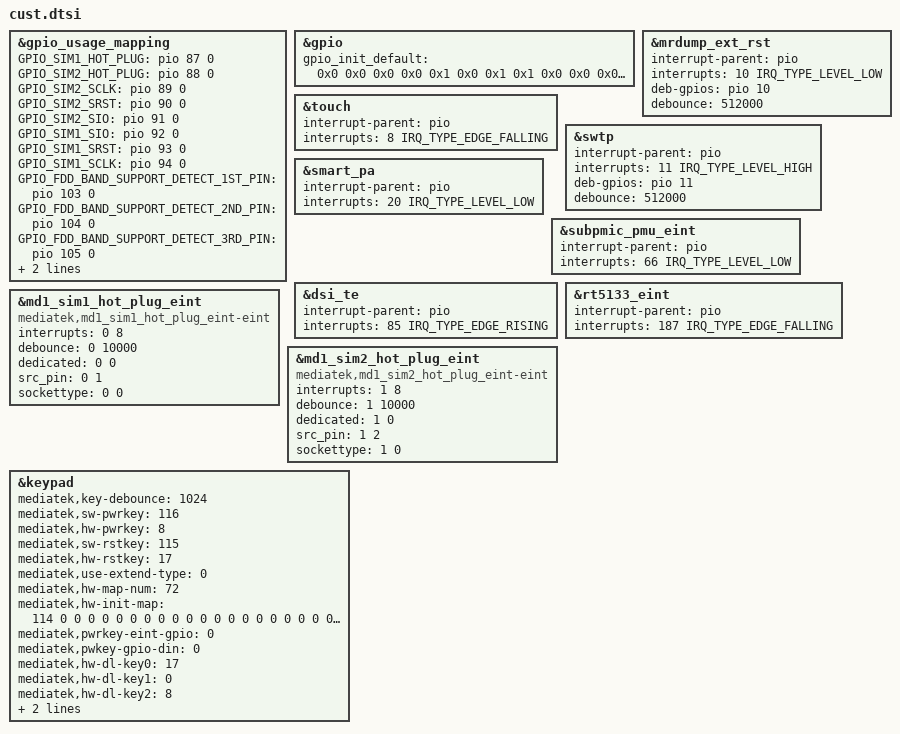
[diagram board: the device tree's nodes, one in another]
/*
 * Manually generated by Mashopy <eliasgheeraert@gmail.com>.
 * 2023-08-16 14:00:00
 * Do Not Modify The File.
*/

/*************************
 * ADC DTSI File
*************************/



/*************************
 * CLK_BUF DTSI File
*************************/



/*************************
 * I2C DTSI File
*************************/



/*************************
 * GPIO DTSI File
*************************/

&gpio_usage_mapping {
	GPIO_SIM1_HOT_PLUG = <&pio 87 0>;
	GPIO_SIM2_HOT_PLUG = <&pio 88 0>;
	GPIO_SIM2_SCLK = <&pio 89 0>;
	GPIO_SIM2_SRST = <&pio 90 0>;
	GPIO_SIM2_SIO = <&pio 91 0>;
	GPIO_SIM1_SIO = <&pio 92 0>;
	GPIO_SIM1_SRST = <&pio 93 0>;
	GPIO_SIM1_SCLK = <&pio 94 0>;
	GPIO_FDD_BAND_SUPPORT_DETECT_1ST_PIN = <&pio 103 0>;
	GPIO_FDD_BAND_SUPPORT_DETECT_2ND_PIN = <&pio 104 0>;
	GPIO_FDD_BAND_SUPPORT_DETECT_3RD_PIN = <&pio 105 0>;
	GPIO_FDD_BAND_SUPPORT_DETECT_4TH_PIN = <&pio 106 0>;
};

&gpio{
	gpio_init_default = <0x0 0x0 0x0 0x0 0x1 0x0 0x1 0x1 0x0 0x0 0x0 0x1 0x0 0x1 0x2 0x0 0x0 0x0 0x1 0x0 0x1 0x3 0x0 0x1 0x0 0x1 0x0 0x1 0x4 0x0 0x0 0x0 0x1 0x0 0x1 0x5 0x0 0x0 0x0 0x1 0x0 0x1 0x6 0x4 0x0 0x0 0x0 0x0 0x1 0x7 0x4 0x0 0x0 0x0 0x0 0x1 0x8 0x0 0x0 0x0 0x0 0x0 0x1 0x9 0x0 0x0 0x0 0x1 0x0 0x1 0xa 0x0 0x0 0x0 0x1 0x1 0x1 0xb 0x0 0x0 0x0 0x1 0x1 0x1 0xc 0x0 0x0 0x0 0x0 0x0 0x1 0xd 0x0 0x0 0x0 0x1 0x0 0x1 0xe 0x0 0x0 0x0 0x1 0x0 0x1 0xf 0x0 0x1 0x0 0x1 0x0 0x1 0x10 0x6 0x0 0x0 0x1 0x0 0x1 0x11 0x6 0x0 0x0 0x1 0x0 0x1 0x12 0x2 0x0 0x0 0x1 0x0 0x1 0x13 0x0 0x0 0x0 0x1 0x0 0x1 0x14 0x0 0x0 0x0 0x1 0x0 0x1 0x15 0x0 0x0 0x0 0x0 0x0 0x1 0x16 0x0 0x0 0x0 0x0 0x0 0x1 0x17 0x0 0x0 0x0 0x1 0x0 0x1 0x18 0x2 0x0 0x0 0x1 0x0 0x1 0x19 0x0 0x0 0x0 0x1 0x0 0x1 0x1a 0x2 0x0 0x0 0x0 0x0 0x1 0x1b 0x2 0x0 0x0 0x0 0x0 0x1 0x1c 0x2 0x0 0x0 0x1 0x0 0x1 0x1d 0x2 0x0 0x0 0x0 0x0 0x1 0x1e 0x0 0x0 0x0 0x0 0x0 0x1 0x1f 0x0 0x0 0x0 0x0 0x0 0x1 0x20 0x0 0x0 0x0 0x1 0x0 0x1 0x21 0x0 0x0 0x0 0x0 0x0 0x1 0x22 0x0 0x1 0x0 0x1 0x0 0x1 0x23 0x0 0x1 0x0 0x1 0x0 0x1 0x24 0x0 0x0 0x0 0x1 0x0 0x1 0x25 0x0 0x0 0x0 0x1 0x0 0x1 0x26 0x1 0x0 0x0 0x0 0x0 0x1 0x27 0x1 0x0 0x0 0x1 0x0 0x1 0x28 0x1 0x0 0x0 0x1 0x1 0x1 0x29 0x1 0x0 0x0 0x1 0x1 0x1 0x2a 0x1 0x0 0x0 0x1 0x1 0x1 0x2b 0x1 0x0 0x0 0x1 0x1 0x1 0x2c 0x1 0x0 0x0 0x0 0x0 0x1 0x2d 0x1 0x0 0x0 0x0 0x0 0x1 0x2e 0x1 0x0 0x0 0x0 0x0 0x1 0x2f 0x1 0x0 0x0 0x0 0x0 0x1 0x30 0x1 0x0 0x0 0x1 0x0 0x1 0x31 0x1 0x0 0x0 0x1 0x1 0x1 0x32 0x1 0x0 0x0 0x1 0x1 0x1 0x33 0x1 0x0 0x0 0x0 0x0 0x1 0x34 0x1 0x0 0x0 0x0 0x0 0x1 0x35 0x1 0x0 0x0 0x0 0x0 0x1 0x36 0x1 0x0 0x0 0x1 0x0 0x1 0x37 0x0 0x0 0x0 0x1 0x0 0x1 0x38 0x0 0x0 0x0 0x1 0x0 0x1 0x39 0x1 0x0 0x0 0x1 0x1 0x1 0x3a 0x1 0x0 0x0 0x1 0x1 0x1 0x3b 0x1 0x0 0x0 0x1 0x1 0x1 0x3c 0x1 0x0 0x0 0x1 0x1 0x1 0x3d 0x1 0x0 0x0 0x0 0x0 0x1 0x3e 0x0 0x1 0x0 0x1 0x0 0x1 0x3f 0x0 0x0 0x0 0x1 0x0 0x1 0x40 0x0 0x0 0x0 0x0 0x0 0x1 0x41 0x0 0x1 0x1 0x1 0x0 0x1 0x42 0x0 0x0 0x0 0x1 0x1 0x1 0x43 0x0 0x1 0x0 0x1 0x0 0x1 0x44 0x0 0x1 0x0 0x0 0x0 0x1 0x45 0x0 0x1 0x0 0x1 0x0 0x1 0x46 0x1 0x0 0x0 0x0 0x0 0x1 0x47 0x1 0x0 0x0 0x0 0x0 0x1 0x48 0x0 0x0 0x0 0x1 0x0 0x1 0x49 0x0 0x0 0x0 0x1 0x0 0x1 0x4a 0x1 0x0 0x0 0x0 0x0 0x1 0x4b 0x1 0x0 0x0 0x0 0x0 0x1 0x4c 0x1 0x0 0x0 0x1 0x1 0x1 0x4d 0x1 0x0 0x0 0x0 0x0 0x1 0x4e 0x1 0x0 0x0 0x1 0x1 0x1 0x4f 0x1 0x0 0x0 0x1 0x1 0x1 0x50 0x1 0x0 0x0 0x1 0x1 0x1 0x51 0x1 0x0 0x0 0x1 0x1 0x1 0x52 0x1 0x0 0x0 0x1 0x1 0x1 0x53 0x1 0x0 0x0 0x1 0x1 0x1 0x54 0x0 0x1 0x0 0x1 0x0 0x1 0x55 0x1 0x0 0x0 0x1 0x0 0x1 0x56 0x0 0x1 0x0 0x1 0x0 0x1 0x57 0x1 0x0 0x0 0x1 0x1 0x1 0x58 0x1 0x0 0x0 0x1 0x1 0x1 0x59 0x1 0x0 0x0 0x0 0x0 0x1 0x5a 0x1 0x0 0x0 0x0 0x0 0x1 0x5b 0x1 0x0 0x0 0x1 0x1 0x1 0x5c 0x1 0x0 0x0 0x1 0x1 0x1 0x5d 0x1 0x0 0x0 0x0 0x0 0x1 0x5e 0x1 0x0 0x0 0x0 0x0 0x1 0x5f 0x0 0x0 0x0 0x1 0x0 0x1 0x60 0x0 0x1 0x0 0x1 0x0 0x1 0x61 0x0 0x0 0x0 0x1 0x0 0x1 0x62 0x1 0x0 0x0 0x1 0x1 0x1 0x63 0x0 0x0 0x0 0x1 0x0 0x1 0x64 0x0 0x1 0x0 0x1 0x0 0x1 0x65 0x1 0x0 0x0 0x1 0x0 0x1 0x66 0x1 0x0 0x0 0x1 0x0 0x1 0x67 0x0 0x0 0x0 0x1 0x0 0x1 0x68 0x0 0x0 0x0 0x1 0x0 0x1 0x69 0x0 0x0 0x0 0x1 0x0 0x1 0x6a 0x0 0x0 0x0 0x1 0x0 0x1 0x6b 0x1 0x0 0x0 0x0 0x0 0x1 0x6c 0x1 0x0 0x0 0x0 0x0 0x1 0x6d 0x1 0x0 0x0 0x0 0x0 0x1 0x6e 0x1 0x0 0x0 0x0 0x0 0x1 0x6f 0x0 0x0 0x0 0x1 0x0 0x1 0x70 0x1 0x0 0x0 0x0 0x0 0x1 0x71 0x0 0x0 0x0 0x1 0x0 0x1 0x72 0x0 0x0 0x0 0x1 0x0 0x1 0x73 0x0 0x0 0x0 0x1 0x0 0x1 0x74 0x0 0x0 0x0 0x1 0x0 0x1 0x75 0x0 0x0 0x0 0x1 0x0 0x1 0x76 0x0 0x0 0x0 0x1 0x0 0x1 0x77 0x0 0x0 0x0 0x1 0x0 0x1 0x78 0x0 0x0 0x0 0x1 0x0 0x1 0x79 0x0 0x0 0x0 0x1 0x0 0x1 0x7a 0x0 0x0 0x0 0x1 0x0 0x1 0x7b 0x0 0x0 0x0 0x0 0x0 0x1 0x7c 0x0 0x0 0x0 0x0 0x0 0x1 0x7d 0x1 0x0 0x0 0x0 0x0 0x0 0x7e 0x1 0x0 0x0 0x1 0x0 0x0 0x7f 0x1 0x0 0x0 0x1 0x0 0x1 0x80 0x1 0x0 0x0 0x1 0x0 0x1 0x81 0x1 0x0 0x0 0x0 0x0 0x0 0x82 0x1 0x0 0x0 0x1 0x0 0x0 0x83 0x1 0x0 0x0 0x0 0x0 0x0 0x84 0x1 0x0 0x0 0x1 0x0 0x0 0x85 0x1 0x0 0x0 0x1 0x1 0x1 0x86 0x1 0x0 0x0 0x1 0x1 0x1 0x87 0x1 0x0 0x0 0x1 0x1 0x1 0x88 0x1 0x0 0x0 0x1 0x1 0x1 0x89 0x0 0x0 0x0 0x1 0x0 0x1 0x8a 0x0 0x0 0x0 0x1 0x0 0x1 0x8b 0x1 0x0 0x0 0x1 0x1 0x1 0x8c 0x1 0x0 0x0 0x0 0x0 0x1 0x8d 0x0 0x0 0x0 0x0 0x0 0x1 0x8e 0x0 0x1 0x0 0x1 0x0 0x1 0x8f 0x7 0x0 0x0 0x1 0x0 0x1 0x90 0x0 0x1 0x0 0x1 0x0 0x1 0x91 0x7 0x0 0x0 0x1 0x0 0x1 0x92 0x0 0x0 0x1 0x1 0x1 0x1 0x93 0x7 0x0 0x0 0x1 0x0 0x1 0x94 0x7 0x0 0x0 0x1 0x0 0x1 0x95 0x0 0x1 0x0 0x1 0x0 0x1 0x96 0x0 0x0 0x0 0x1 0x0 0x1 0x97 0x0 0x0 0x0 0x1 0x0 0x1 0x98 0x0 0x0 0x0 0x1 0x0 0x1 0x99 0x0 0x0 0x0 0x1 0x0 0x1 0x9a 0x0 0x0 0x0 0x1 0x0 0x1 0x9b 0x0 0x0 0x0 0x1 0x0 0x1 0x9c 0x0 0x0 0x0 0x1 0x0 0x1 0x9d 0x0 0x0 0x0 0x1 0x1 0x1 0x9e 0x1 0x0 0x0 0x1 0x1 0x1 0x9f 0x0 0x1 0x0 0x1 0x0 0x1 0xa0 0x1 0x0 0x0 0x1 0x0 0x1 0xa1 0x0 0x1 0x1 0x1 0x1 0x1 0xa2 0x0 0x1 0x0 0x1 0x0 0x1 0xa3 0x1 0x0 0x0 0x1 0x0 0x1 0xa4 0x1 0x0 0x0 0x0 0x0 0x1 0xa5 0x0 0x1 0x0 0x1 0x1 0x1 0xa6 0x0 0x0 0x0 0x1 0x0 0x1 0xa7 0x0 0x0 0x0 0x0 0x0 0x1 0xa8 0x2 0x0 0x0 0x1 0x0 0x1 0xa9 0x0 0x1 0x0 0x0 0x0 0x1 0xaa 0x2 0x1 0x0 0x0 0x0 0x1 0xab 0x2 0x1 0x0 0x0 0x0 0x1 0xad 0x1 0x0 0x0 0x1 0x1 0x1 0xae 0x1 0x0 0x0 0x1 0x1 0x1 0xaf 0x1 0x0 0x0 0x1 0x1 0x1 0xb0 0x1 0x0 0x0 0x1 0x1 0x1 0xb1 0x1 0x0 0x0 0x1 0x1 0x1 0xb2 0x1 0x0 0x0 0x1 0x1 0x1 0xb3 0x1 0x0 0x0 0x1 0x1 0x1 0xb4 0x1 0x0 0x0 0x1 0x1 0x1 0xb5 0x1 0x0 0x0 0x1 0x1 0x1 0xb6 0x1 0x0 0x0 0x1 0x1 0x1 0xb7 0x1 0x0 0x0 0x1 0x1 0x1 0xb8 0x1 0x0 0x0 0x1 0x1 0x1 0xb9 0x1 0x0 0x0 0x1 0x1 0x1 0xba 0x1 0x0 0x0 0x1 0x1 0x1 0xbb 0x0 0x0 0x0 0x0 0x0 0x1 0xbc 0x0 0x1 0x0 0x1 0x0 0x1 0xbd 0x0 0x0 0x0 0x1 0x0 0x1 0xbe 0x0 0x0 0x0 0x1 0x0 0x1 0xbf 0x0 0x0 0x0 0x1 0x0 0x1 0xc0 0x0 0x0 0x0 0x1 0x0 0x1 0xc1 0x0 0x0 0x0 0x1 0x0 0x1 0xc2 0x0 0x0 0x0 0x1 0x0 0x1 0xc3 0x0 0x0 0x0 0x1 0x0 0x1 0xc4 0x0 0x0 0x0 0x1 0x0 0x1 0xc5 0x0 0x0 0x0 0x1 0x0 0x1 0xc6 0x0 0x0 0x0 0x1 0x0 0x1 0xc7 0x0 0x1 0x0 0x1 0x0 0x1 0xc8 0x0 0x1 0x0 0x1 0x0 0x1 0xc9 0x0 0x1 0x0 0x1 0x0 0x1 0xca 0x0 0x1 0x0 0x1 0x0 0x1 0xcb 0x0 0x0 0x0 0x0 0x0 0x1 0xcc 0x0 0x1 0x0 0x1 0x0 0x1 0xcd 0x0 0x0 0x0 0x1 0x0 0x1 0xce 0x0 0x0 0x0 0x0 0x0 0x1 0xcf 0x0 0x0 0x0 0x1 0x0 0x1 0xd0 0x0 0x0 0x0 0x1 0x0 0x1 0xd1 0x0 0x0 0x0 0x1 0x0 0x1 0xd2 0x0 0x0 0x0 0x1 0x0 0x1 0xd3 0x0 0x0 0x0 0x1 0x0 0x1 0xd4 0x0 0x0 0x0 0x1 0x0 0x1 0xd5 0x0 0x0 0x0 0x1 0x0 0x1 0xd6 0x0 0x0 0x0 0x1 0x0 0x1 0xd7 0x0 0x0 0x0 0x1 0x0 0x1 0xd8 0x0 0x0 0x0 0x1 0x0 0x1 0xd9 0x0 0x0 0x0 0x1 0x0 0x1 0xda 0x0 0x0 0x0 0x1 0x0 0x1 0xdb 0x0 0x0 0x0 0x1 0x0 0x1 0xdc 0x0 0x0 0x0 0x1 0x0 0x1 0xdd 0x0 0x0 0x0 0x1 0x0 0x1 0xde 0x1 0x0 0x0 0x1 0x0 0x1 0xdf 0x0 0x0 0x0 0x1 0x0 0x1 0xe0 0x0 0x0 0x0 0x1 0x0 0x1 0xe1 0x0 0x0 0x0 0x1 0x0 0x1 0xe2 0x0 0x0 0x0 0x1 0x0 0x1 0xe3 0x0 0x0 0x0 0x1 0x0 0x1 0xe4 0x0 0x0 0x0 0x1 0x0 0x1 0xe5 0x0 0x0 0x0 0x1 0x0 0x1 0xe6 0x0 0x0 0x0 0x1 0x0 0x1 0xe7 0x0 0x0 0x0 0x1 0x0 0x1 0xe8 0x0 0x0 0x0 0x1 0x0 0x1 0xe9 0x0 0x0 0x0 0x1 0x0 0x1 0xea 0x0 0x0 0x0 0x1 0x0 0x0 0xeb 0x0 0x0 0x0 0x1 0x0 0x0 0xec 0x0 0x0 0x0 0x1 0x0 0x0 0xed 0x0 0x0 0x0 0x1 0x0 0x0 0xee 0x0 0x0 0x0 0x1 0x0 0x0 0xef 0x0 0x0 0x0 0x1 0x0 0x0 0xf0 0x0 0x0 0x0 0x1 0x0 0x0 0xf1 0x0 0x0 0x0 0x1 0x0 0x0 0xf2 0x0 0x0 0x0 0x1 0x0 0x0 0xf3 0x0 0x0 0x0 0x1 0x0 0x0 0xf4 0x0 0x0 0x0 0x1 0x0 0x0>;
};


/*************************
 * EINT DTSI File
*************************/

#include <dt-bindings/interrupt-controller/irq.h>
#include <dt-bindings/interrupt-controller/arm-gic.h>

&touch {
	interrupt-parent = <&pio>;
	interrupts = <8 IRQ_TYPE_EDGE_FALLING>;
	status = "okay";
};

&mrdump_ext_rst {
	interrupt-parent = <&pio>;
	interrupts = <10 IRQ_TYPE_LEVEL_LOW>;
	deb-gpios = <&pio 10 0>;
	debounce = <512000>;
	status = "okay";
};

&swtp {
	interrupt-parent = <&pio>;
	interrupts = <11 IRQ_TYPE_LEVEL_HIGH>;
	deb-gpios = <&pio 11 0>;
	debounce = <512000>;
	status = "okay";
};

&smart_pa {
	interrupt-parent = <&pio>;
	interrupts = <20 IRQ_TYPE_LEVEL_LOW>;
	status = "okay";
};

&subpmic_pmu_eint {
	interrupt-parent = <&pio>;
	interrupts = <66 IRQ_TYPE_LEVEL_LOW>;
	status = "okay";
};

&dsi_te {
	interrupt-parent = <&pio>;
	interrupts = <85 IRQ_TYPE_EDGE_RISING>;
	status = "okay";
};

&rt5133_eint {
	interrupt-parent = <&pio>;
	interrupts = <187 IRQ_TYPE_EDGE_FALLING>;
	status = "okay";
};



/*************************
 * MD1_EINT DTSI File
*************************/

&md1_sim1_hot_plug_eint {
	compatible = "mediatek,md1_sim1_hot_plug_eint-eint";
	interrupts = <0 8>;
	debounce = <0 10000>;
	dedicated = <0 0>;
	src_pin = <0 1>;
	sockettype = <0 0>;
	status = "okay";
};

&md1_sim2_hot_plug_eint {
	compatible = "mediatek,md1_sim2_hot_plug_eint-eint";
	interrupts = <1 8>;
	debounce = <1 10000>;
	dedicated = <1 0>;
	src_pin = <1 2>;
	sockettype = <1 0>;
	status = "okay";
};



/*************************
 * PMIC DTSI File
*************************/



/*************************
 * POWER DTSI File
*************************/



/*************************
 * KPD DTSI File
*************************/

&keypad {
	mediatek,key-debounce = <1024>;
	mediatek,sw-pwrkey = <116>;
	mediatek,hw-pwrkey = <8>;
	mediatek,sw-rstkey  = <115>;
	mediatek,hw-rstkey = <17>;
	mediatek,use-extend-type = <0>;
	/*HW Keycode [0~71] -> Linux Keycode*/
	mediatek,hw-map-num = <72>;
	mediatek,hw-init-map = <114 0 0 0 0 0 0 0 0 0 0 0 0 0 0 0 0 0 0 0 0 0 0 0 0 0 0 0 0 0 0 0 0 0 0 0 0 0 0 0 0 0 0 0 0 0 0 0 0 0 0 0 0 0 0 0 0 0 0 0 0 0 0 0 0 0 0 0 0 0 0 0>;
	mediatek,pwrkey-eint-gpio = <0>;
	mediatek,pwkey-gpio-din  = <0>;
	mediatek,hw-dl-key0 = <17>;
	mediatek,hw-dl-key1 = <0>;
	mediatek,hw-dl-key2 = <8>;
	mediatek,hw-recovery-key = <17>;
	mediatek,hw-factory-key = <0>;
	status = "okay";
};
